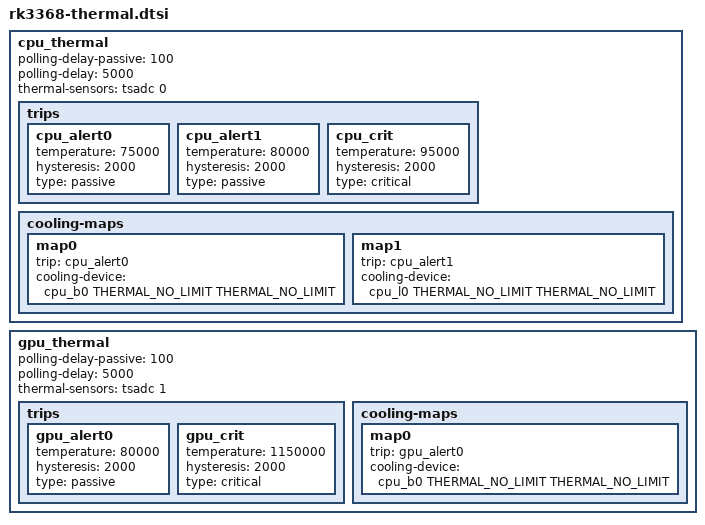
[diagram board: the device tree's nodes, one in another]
/*
 * Device Tree Source for RK3368 SoC thermal
 *
 * Copyright (c) 2015, Fuzhou Rockchip Electronics Co., Ltd
 * Caesar Wang <wxt@rock-chips.com>
 *
 * This file is dual-licensed: you can use it either under the terms
 * of the GPL or the X11 license, at your option. Note that this dual
 * licensing only applies to this file, and not this project as a
 * whole.
 *
 *  a) This file is free software; you can redistribute it and/or
 *     modify it under the terms of the GNU General Public License as
 *     published by the Free Software Foundation; either version 2 of the
 *     License, or (at your option) any later version.
 *
 *     This file is distributed in the hope that it will be useful,
 *     but WITHOUT ANY WARRANTY; without even the implied warranty of
 *     MERCHANTABILITY or FITNESS FOR A PARTICULAR PURPOSE.  See the
 *     GNU General Public License for more details.
 *
 * Or, alternatively,
 *
 *  b) Permission is hereby granted, free of charge, to any person
 *     obtaining a copy of this software and associated documentation
 *     files (the "Software"), to deal in the Software without
 *     restriction, including without limitation the rights to use,
 *     copy, modify, merge, publish, distribute, sublicense, and/or
 *     sell copies of the Software, and to permit persons to whom the
 *     Software is furnished to do so, subject to the following
 *     conditions:
 *
 *     The above copyright notice and this permission notice shall be
 *     included in all copies or substantial portions of the Software.
 *
 *     THE SOFTWARE IS PROVIDED "AS IS", WITHOUT WARRANTY OF ANY KIND,
 *     EXPRESS OR IMPLIED, INCLUDING BUT NOT LIMITED TO THE WARRANTIES
 *     OF MERCHANTABILITY, FITNESS FOR A PARTICULAR PURPOSE AND
 *     NONINFRINGEMENT. IN NO EVENT SHALL THE AUTHORS OR COPYRIGHT
 *     HOLDERS BE LIABLE FOR ANY CLAIM, DAMAGES OR OTHER LIABILITY,
 *     WHETHER IN AN ACTION OF CONTRACT, TORT OR OTHERWISE, ARISING
 *     FROM, OUT OF OR IN CONNECTION WITH THE SOFTWARE OR THE USE OR
 *     OTHER DEALINGS IN THE SOFTWARE.
 */

#include <dt-bindings/thermal/thermal.h>

cpu_thermal: cpu_thermal {
	polling-delay-passive = <100>; /* milliseconds */
	polling-delay = <5000>; /* milliseconds */

	thermal-sensors = <&tsadc 0>;

	trips {
		cpu_alert0: cpu_alert0 {
			temperature = <75000>; /* millicelsius */
			hysteresis = <2000>; /* millicelsius */
			type = "passive";
		};
		cpu_alert1: cpu_alert1 {
			temperature = <80000>; /* millicelsius */
			hysteresis = <2000>; /* millicelsius */
			type = "passive";
		};
		cpu_crit: cpu_crit {
			temperature = <95000>; /* millicelsius */
			hysteresis = <2000>; /* millicelsius */
			type = "critical";
		};
	};

	cooling-maps {
		map0 {
			trip = <&cpu_alert0>;
			cooling-device =
				<&cpu_b0 THERMAL_NO_LIMIT THERMAL_NO_LIMIT>;
		};
		map1 {
			trip = <&cpu_alert1>;
			cooling-device =
				<&cpu_l0 THERMAL_NO_LIMIT THERMAL_NO_LIMIT>;
		};
	};
};

gpu_thermal: gpu_thermal {
	polling-delay-passive = <100>; /* milliseconds */
	polling-delay = <5000>; /* milliseconds */

	thermal-sensors = <&tsadc 1>;

	trips {
		gpu_alert0: gpu_alert0 {
			temperature = <80000>; /* millicelsius */
			hysteresis = <2000>; /* millicelsius */
			type = "passive";
		};
		gpu_crit: gpu_crit {
			temperature = <1150000>; /* millicelsius */
			hysteresis = <2000>; /* millicelsius */
			type = "critical";
		};
	};

	cooling-maps {
		map0 {
			trip = <&gpu_alert0>;
			cooling-device =
				<&cpu_b0 THERMAL_NO_LIMIT THERMAL_NO_LIMIT>;
		};
	};
};
